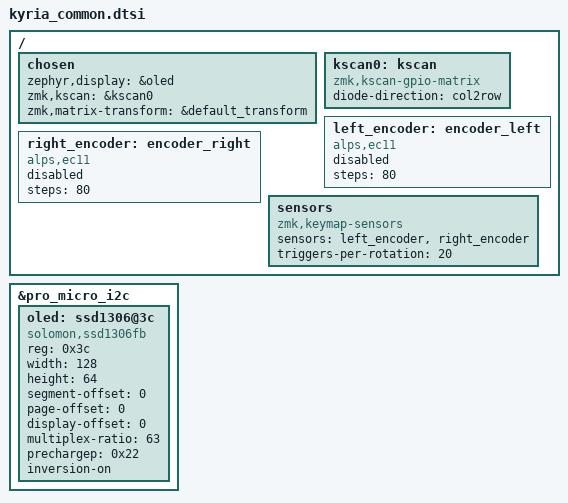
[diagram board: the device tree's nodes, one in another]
/*
 * Copyright (c) 2022 The ZMK Contributors
 *
 * SPDX-License-Identifier: MIT
 */

#include <dt-bindings/zmk/matrix_transform.h>

/ {
    chosen {
        zephyr,display = &oled;
        zmk,kscan = &kscan0;
        zmk,matrix-transform = &default_transform;
    };

    kscan0: kscan {
        compatible = "zmk,kscan-gpio-matrix";

        diode-direction = "col2row";
    };

    left_encoder: encoder_left {
        compatible = "alps,ec11";
        steps = <80>;
        status = "disabled";
    };

    right_encoder: encoder_right {
        compatible = "alps,ec11";
        steps = <80>;
        status = "disabled";
    };

    sensors: sensors {
        compatible = "zmk,keymap-sensors";
        sensors = <&left_encoder &right_encoder>;
        triggers-per-rotation = <20>;
    };

    // TODO: RGB node(s)
};

&pro_micro_i2c {
    status = "okay";

    oled: ssd1306@3c {
        compatible = "solomon,ssd1306fb";
        reg = <0x3c>;
        width = <128>;
        height = <64>;
        segment-offset = <0>;
        page-offset = <0>;
        display-offset = <0>;
        multiplex-ratio = <63>;
        prechargep = <0x22>;
        inversion-on;
    };
};
